# STM32G0B0 register map
File version: 1.0
CPU: CM0 r0p1, little endian, MPU, no FPU, 4 interrupt priority bits
Registers are 32-bit, read-write, reset 0x0 unless marked. A register's access mark holds for its fields unless they carry their own. Offsets are from the block's base; [hi:lo] are bit positions.

## IWDG — Independent watchdog
Base 0x40003000
0x00 IWDG_KR wo — Key register
  [15:0] KEY — Key value (write only, read 0x0000)
0x04 IWDG_PR — Prescaler register
  [2:0] PR — Prescaler divider These bits are write access protected see . They are written by software to select the prescaler divider feeding the counter clock. PVU bit of the must be reset in order to be able to change the prescaler divider. Note: Reading this register returns the prescaler value from the VDD voltage domain. This value may not be up to date/valid if a write operation to this register is ongoing. For this reason the value read from this register is valid only when the PVU bit in the status register (IWDG_SR) is reset.
    0=divider /4; 1=divider /8; 2=divider /16; 3=divider /32; 4=divider /64; 5=divider /128; 6=divider /256; 7=divider /256
0x08 IWDG_RLR reset 0xFFF — Reload register
  [11:0] RL — Watchdog counter reload value
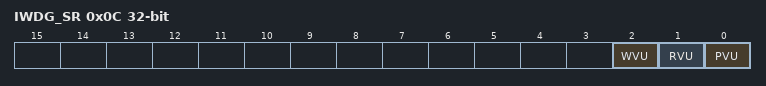
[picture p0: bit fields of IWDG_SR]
0x0C IWDG_SR ro — Status register
  [2] WVU — Watchdog counter window value update This bit is set by hardware to indicate that an update of the window value is ongoing. It is reset by hardware when the reload value update operation is completed in the VDD voltage domain (takes up to five LSI cycles). Window value can be updated only when WVU bit is reset.
  [1] RVU — Watchdog counter reload value update This bit is set by hardware to indicate that an update of the reload value is ongoing. It is reset by hardware when the reload value update operation is completed in the VDD voltage domain (takes up to five LSI cycles). Reload value can be updated only when RVU bit is reset.
  [0] PVU — Watchdog prescaler value update This bit is set by hardware to indicate that an update of the prescaler value is ongoing. It is reset by hardware when the prescaler update operation is completed in the VDD voltage domain (takes up to five LSI cycles). Prescaler value can be updated only when PVU bit is reset.
0x10 IWDG_WINR reset 0xFFF — Window register
  [11:0] WIN — Watchdog counter window value

## RNG — Random number generator
Base 0x40025000
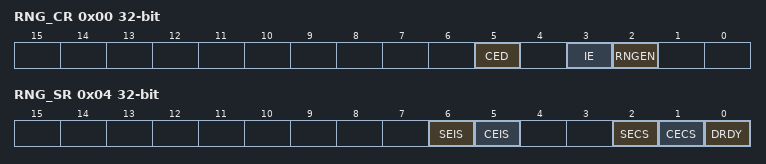
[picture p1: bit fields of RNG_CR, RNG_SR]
0x00 RNG_CR — control register
  [5] CED — Clock error detection The clock error detection cannot be enabled nor disabled on-the-fly when the RNG is enabled, i.e. to enable or disable CED the RNG must be disabled.
    0=Clock error detection is enable; 1=Clock error detection is disable
  [3] IE — Interrupt Enable
    0=RNG Interrupt is disabled; 1=RNG Interrupt is enabled. An interrupt is pending as soon as DRDY='1', SEIS='1' or CEIS=1 in the RNG_SR register.
  [2] RNGEN — True random number generator enable
    0=True random number generator is disabled. Analog noise sources are powered off and logic clocked by the RNG clock is gated.; 1=True random number generator is enabled
0x04 RNG_SR access per field — status register
  [6] SEIS rw — Seed error interrupt status This bit is set at the same time as SECS. It is cleared by writing 0. Writing 1 has no effect. An interrupt is pending if IE = 1 in the RNG_CR register.
    0=No faulty sequence detected; 1=At least one faulty sequence has been detected. See SECS bit description for details.
  [5] CEIS rw — Clock error interrupt status This bit is set at the same time as CECS. It is cleared by writing 0. Writing 1 has no effect. An interrupt is pending if IE = 1 in the RNG_CR register.
    0=The RNG clock is correct (fRNGCLK> fHCLK/32); 1=The RNG has been detected too slow (fRNGCLK< fHCLK/32)
  [2] SECS ro — Seed error current status One of the noise source has provided more than 64 consecutive bits at a constant value (â0â or â1â), or more than 32 consecutive occurrence of two bit patterns (â01â or â10â) Both noise sources have delivered more than 32 consecutive bits at a constant value (â0â or â1â), or more than 16 consecutive occurrence of two bit patterns (â01â or â10â)
    0=No faulty sequence has currently been detected. If the SEIS bit is set, this means that a faulty sequence was detected and the situation has been recovered.; 1=At least one of the following faulty sequence has been detected:
  [1] CECS ro — Clock error current status Note: CECS bit is valid only if the CED bit in the RNG_CR register is set to 0.
    0=The RNG clock is correct (fRNGCLK> fHCLK/32). If the CEIS bit is set, this means that a slow clock was detected and the situation has been recovered.; 1=The RNG clock is too slow (fRNGCLK< fHCLK/32)
  [0] DRDY ro — Data Ready Once the output buffer becomes empty (after reading the RNG_DR register), this bit returns to 0 until a new random value is generated. Note: The DRDY bit can rise when the peripheral is disabled (RNGEN=0 in the RNG_CR register). If IE=1 in the RNG_CR register, an interrupt is generated when DRDY=1.
    0=The RNG_DR register is not yet valid, no random data is available; 1=The RNG_DR register contains valid random data
0x08 RNG_DR ro — data register
  [31:0] RNDATA — Random data

## VREFBUF — System configuration controller
Base 0x40010030
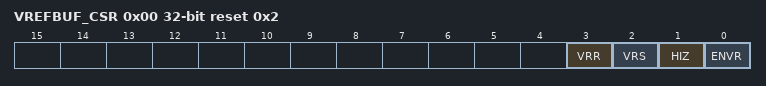
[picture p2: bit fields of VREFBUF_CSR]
0x00 VREFBUF_CSR access per field reset 0x2 — VREFBUF control and status register
  [3] VRR ro — Voltage reference buffer ready
    0=the voltage reference buffer output is not ready; 1=the voltage reference buffer output reached the requested level
  [2] VRS rw — Voltage reference scale This bit selects the value generated by the voltage reference buffer.
    0=Voltage reference set to VREF_OUT1 (around 2.048 V); 1=Voltage reference set to VREF_OUT2 (around 2.5 V)
  [1] HIZ rw — High impedance mode This bit controls the analog switch to connect or not the VREF+ pin. Refer to for the mode descriptions depending on ENVR bit configuration.
    0=VREF+ pin is internally connected to the voltage reference buffer output; 1=VREF+ pin is high impedance
  [0] ENVR rw — Voltage reference buffer mode enable This bit is used to enable the voltage reference buffer mode.
    0=Internal voltage reference mode disable (external voltage reference mode); 1=Internal voltage reference mode (reference buffer enable or hold mode) enable
0x04 VREFBUF_CCR — VREFBUF calibration control register
  [5:0] TRIM — Trimming code These bits are automatically initialized after reset with the trimming value stored in the Flash memory during the production test. Writing into these bits allows the tuning of the internal reference buffer voltage.

## WWDG — System window watchdog
Base 0x40002C00
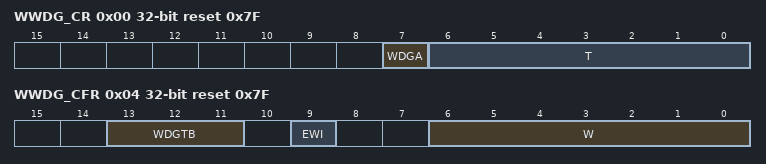
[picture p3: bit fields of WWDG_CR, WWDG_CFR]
0x00 WWDG_CR reset 0x7F — Control register
  [7] WDGA — Activation bit This bit is set by software and only cleared by hardware after a reset. When WDGAÂ =Â 1, the watchdog can generate a reset.
    0=Watchdog disabled; 1=Watchdog enabled
  [6:0] T — 7-bit counter (MSB to LSB) These bits contain the value of the watchdog counter, decremented every (4096 x 2WDGTB[1:0]) PCLK cycles. A reset is produced when it is decremented from 0x40 to 0x3F (T6 becomes cleared).
0x04 WWDG_CFR reset 0x7F — Configuration register
  [13:11] WDGTB — Timer base The timebase of the prescaler can be modified as follows:
    0=CK Counter Clock (PCLK div 4096) div 1; 1=CK Counter Clock (PCLK div 4096) div 2; 2=CK Counter Clock (PCLK div 4096) div 4; 3=CK Counter Clock (PCLK div 4096) div 8; 4=CK Counter Clock (PCLK div 4096) div 16; 5=CK Counter Clock (PCLK div 4096) div 32; 6=CK Counter Clock (PCLK div 4096) div 64; 7=CK Counter Clock (PCLK div 4096) div 128
  [9] EWI — Early wakeup interrupt When set, an interrupt occurs whenever the counter reaches the value 0x40. This interrupt is only cleared by hardware after a reset.
  [6:0] W — 7-bit window value These bits contain the window value to be compared with the down-counter.
0x08 WWDG_SR — Status register
  [0] EWIF — Early wakeup interrupt flag
